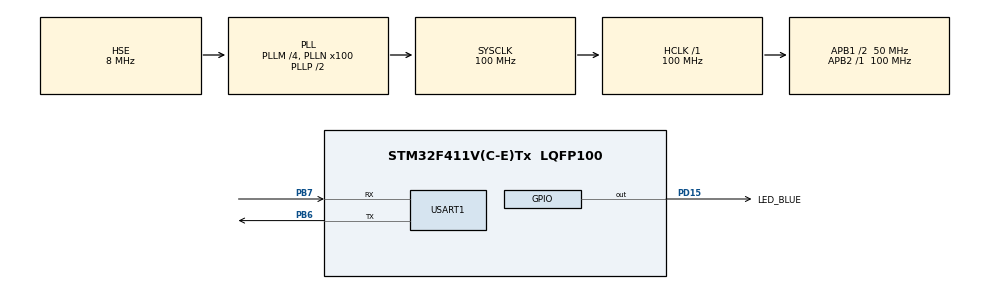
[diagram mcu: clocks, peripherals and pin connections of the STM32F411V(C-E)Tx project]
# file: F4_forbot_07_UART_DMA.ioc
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Dma.Request0=USART1_TX
Dma.Request1=USART1_RX
Dma.USART1_RX.1.Direction=DMA_PERIPH_TO_MEMORY
Dma.USART1_RX.1.FIFOMode=DMA_FIFOMODE_DISABLE
Dma.USART1_RX.1.Instance=DMA2_Stream2
Dma.USART1_RX.1.MemDataAlignment=DMA_MDATAALIGN_BYTE
Dma.USART1_RX.1.MemInc=DMA_MINC_ENABLE
Dma.USART1_RX.1.Mode=DMA_NORMAL
Dma.USART1_RX.1.PeriphDataAlignment=DMA_PDATAALIGN_BYTE
Dma.USART1_RX.1.PeriphInc=DMA_PINC_DISABLE
Dma.USART1_RX.1.Priority=DMA_PRIORITY_LOW
Dma.USART1_TX.0.Direction=DMA_MEMORY_TO_PERIPH
Dma.USART1_TX.0.FIFOMode=DMA_FIFOMODE_DISABLE
Dma.USART1_TX.0.Instance=DMA2_Stream7
Dma.USART1_TX.0.MemDataAlignment=DMA_MDATAALIGN_BYTE
Dma.USART1_TX.0.MemInc=DMA_MINC_ENABLE
Dma.USART1_TX.0.Mode=DMA_NORMAL
Dma.USART1_TX.0.PeriphDataAlignment=DMA_PDATAALIGN_BYTE
Dma.USART1_TX.0.PeriphInc=DMA_PINC_DISABLE
Dma.USART1_TX.0.Priority=DMA_PRIORITY_LOW
Mcu.Family=STM32F4
Mcu.Name=STM32F411V(C-E)Tx
Mcu.Package=LQFP100
NVIC.DMA2_Stream2_IRQn=true\:0\:0\:false\:false\:true\:false\:true
NVIC.DMA2_Stream7_IRQn=true\:0\:0\:false\:false\:true\:false\:true
NVIC.PriorityGroup=NVIC_PRIORITYGROUP_4
NVIC.USART1_IRQn=true\:0\:0\:false\:false\:true\:true\:true
PB6.Mode=Asynchronous
PB6.Signal=USART1_TX
PB7.Mode=Asynchronous
PB7.Signal=USART1_RX
PD15.GPIO_Label=LED_BLUE
PD15.Signal=GPIO_Output
PH0\ -\ OSC_IN.Mode=HSE-External-Oscillator
PH0\ -\ OSC_IN.Signal=RCC_OSC_IN
PH1\ -\ OSC_OUT.Mode=HSE-External-Oscillator
PH1\ -\ OSC_OUT.Signal=RCC_OSC_OUT
ProjectManager.HeapSize=0x200
ProjectManager.StackSize=0x400
ProjectManager.TargetToolchain=SW4STM32
RCC.48MHZClocksFreq_Value=50000000
RCC.AHBFreq_Value=100000000
RCC.APB1CLKDivider=RCC_HCLK_DIV2
RCC.APB1Freq_Value=50000000
RCC.APB1TimFreq_Value=100000000
RCC.APB2Freq_Value=100000000
RCC.APB2TimFreq_Value=100000000
RCC.CortexFreq_Value=100000000
RCC.HCLKFreq_Value=100000000
RCC.HSE_VALUE=8000000
RCC.HSI_VALUE=16000000
RCC.LSE_VALUE=32768
RCC.PLLM=4
RCC.PLLN=100
RCC.PLLSourceVirtual=RCC_PLLSOURCE_HSE
RCC.SYSCLKFreq_VALUE=100000000
RCC.SYSCLKSource=RCC_SYSCLKSOURCE_PLLCLK
RCC.VCOOutputFreq_Value=200000000
USART1.VirtualMode=VM_ASYNC
board=custom

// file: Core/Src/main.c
/* USER CODE BEGIN Header */
/**
  ******************************************************************************
  * @file           : main.c
  * @brief          : Main program body
  ******************************************************************************
  * @attention
  *
  * <h2><center>&copy; Copyright (c) 2021 STMicroelectronics.
  * All rights reserved.</center></h2>
  *
  * This software component is licensed by ST under BSD 3-Clause license,
  * the "License"; You may not use this file except in compliance with the
  * License. You may obtain a copy of the License at:
  *                        opensource.org/licenses/BSD-3-Clause
  *
  ******************************************************************************
  */
/* USER CODE END Header */
#include "main.h"

UART_HandleTypeDef huart1;
DMA_HandleTypeDef hdma_usart1_tx;
DMA_HandleTypeDef hdma_usart1_rx;

/* USER CODE BEGIN PV */
uint8_t Data[40];
uint8_t Received[10];
/* USER CODE END PV */

void SystemClock_Config(void);
static void MX_GPIO_Init(void);
static void MX_USART1_UART_Init(void);
static void MX_DMA_Init(void);
/* USER CODE BEGIN PFP */

void HAL_UART_RxCpltCallback(UART_HandleTypeDef *huart){

	uint16_t size = 0;
	size=sprintf(Data, "Odebrana wiadomosc: %s\n\r", Received);
	HAL_UART_Transmit_DMA(&huart1, Data, size); // Rozpoczecie nadawania danych z wykorzystaniem przerwan
	HAL_UART_Receive_DMA(&huart1, Received, 10); // Ponowne w³¹czenie nas³uchiwania
	HAL_GPIO_TogglePin(LED_BLUE_GPIO_Port, LED_BLUE_Pin);

}
/* USER CODE END PFP */

int main(void)
{

  /* MCU Configuration--------------------------------------------------------*/

  /* Reset of all peripherals, Initializes the Flash interface and the Systick. */
  HAL_Init();

  /* Configure the system clock */
  SystemClock_Config();

  /* Initialize all configured peripherals */
  MX_GPIO_Init();
  MX_USART1_UART_Init();
  MX_DMA_Init();
  /* USER CODE BEGIN 2 */
  HAL_UART_Receive_DMA(&huart1,Received,10);
  /* USER CODE END 2 */

  /* Infinite loop */
  while (1)
  {

  }
}

void SystemClock_Config(void)
{
  RCC_OscInitTypeDef RCC_OscInitStruct = {0};
  RCC_ClkInitTypeDef RCC_ClkInitStruct = {0};

  /** Configure the main internal regulator output voltage
  */
  __HAL_RCC_PWR_CLK_ENABLE();
  __HAL_PWR_VOLTAGESCALING_CONFIG(PWR_REGULATOR_VOLTAGE_SCALE1);
  /** Initializes the RCC Oscillators according to the specified parameters
  * in the RCC_OscInitTypeDef structure.
  */
  RCC_OscInitStruct.OscillatorType = RCC_OSCILLATORTYPE_HSE;
  RCC_OscInitStruct.HSEState = RCC_HSE_ON;
  RCC_OscInitStruct.PLL.PLLState = RCC_PLL_ON;
  RCC_OscInitStruct.PLL.PLLSource = RCC_PLLSOURCE_HSE;
  RCC_OscInitStruct.PLL.PLLM = 4;
  RCC_OscInitStruct.PLL.PLLN = 100;
  RCC_OscInitStruct.PLL.PLLP = RCC_PLLP_DIV2;
  RCC_OscInitStruct.PLL.PLLQ = 4;
  if (HAL_RCC_OscConfig(&RCC_OscInitStruct) != HAL_OK)
  {
    Error_Handler();
  }
  /** Initializes the CPU, AHB and APB buses clocks
  */
  RCC_ClkInitStruct.ClockType = RCC_CLOCKTYPE_HCLK|RCC_CLOCKTYPE_SYSCLK
                              |RCC_CLOCKTYPE_PCLK1|RCC_CLOCKTYPE_PCLK2;
  RCC_ClkInitStruct.SYSCLKSource = RCC_SYSCLKSOURCE_PLLCLK;
  RCC_ClkInitStruct.AHBCLKDivider = RCC_SYSCLK_DIV1;
  RCC_ClkInitStruct.APB1CLKDivider = RCC_HCLK_DIV2;
  RCC_ClkInitStruct.APB2CLKDivider = RCC_HCLK_DIV1;

  if (HAL_RCC_ClockConfig(&RCC_ClkInitStruct, FLASH_LATENCY_3) != HAL_OK)
  {
    Error_Handler();
  }
}

static void MX_USART1_UART_Init(void)
{

  huart1.Instance = USART1;
  huart1.Init.BaudRate = 115200;
  huart1.Init.WordLength = UART_WORDLENGTH_8B;
  huart1.Init.StopBits = UART_STOPBITS_1;
  huart1.Init.Parity = UART_PARITY_NONE;
  huart1.Init.Mode = UART_MODE_TX_RX;
  huart1.Init.HwFlowCtl = UART_HWCONTROL_NONE;
  huart1.Init.OverSampling = UART_OVERSAMPLING_16;
  if (HAL_UART_Init(&huart1) != HAL_OK)
  {
    Error_Handler();
  }

}

static void MX_DMA_Init(void)
{

  /* DMA controller clock enable */
  __HAL_RCC_DMA2_CLK_ENABLE();

  /* DMA interrupt init */
  /* DMA2_Stream2_IRQn interrupt configuration */
  HAL_NVIC_SetPriority(DMA2_Stream2_IRQn, 1, 0);
  HAL_NVIC_EnableIRQ(DMA2_Stream2_IRQn);
  /* DMA2_Stream7_IRQn interrupt configuration */
  HAL_NVIC_SetPriority(DMA2_Stream7_IRQn, 1, 0);
  HAL_NVIC_EnableIRQ(DMA2_Stream7_IRQn);

}

static void MX_GPIO_Init(void)
{
  GPIO_InitTypeDef GPIO_InitStruct = {0};

  /* GPIO Ports Clock Enable */
  __HAL_RCC_GPIOH_CLK_ENABLE();
  __HAL_RCC_GPIOD_CLK_ENABLE();
  __HAL_RCC_GPIOB_CLK_ENABLE();

  /*Configure GPIO pin Output Level */
  HAL_GPIO_WritePin(LED_BLUE_GPIO_Port, LED_BLUE_Pin, GPIO_PIN_RESET);

  /*Configure GPIO pin : LED_BLUE_Pin */
  GPIO_InitStruct.Pin = LED_BLUE_Pin;
  GPIO_InitStruct.Mode = GPIO_MODE_OUTPUT_PP;
  GPIO_InitStruct.Pull = GPIO_NOPULL;
  GPIO_InitStruct.Speed = GPIO_SPEED_FREQ_LOW;
  HAL_GPIO_Init(LED_BLUE_GPIO_Port, &GPIO_InitStruct);

}

void Error_Handler(void)
{
  __disable_irq();
  while (1)
  {
  }
}

/************************ (C) COPYRIGHT STMicroelectronics *****END OF FILE****/
